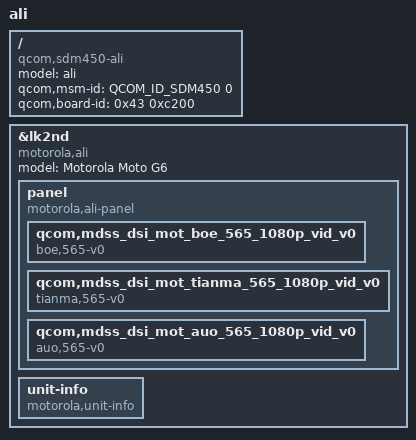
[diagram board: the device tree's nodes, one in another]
// SPDX-License-Identifier: GPL-2.0-only

#include <skeleton64.dtsi>
#include <lk2nd.dtsi>
#include <motorola-carrier-channel-ids.dtsi>

// The stock bootloader uses all these values to select the right DTB
/ {
	model = "ali";
	compatible = "qcom,sdm450-ali", "qcom,sdm450-moto", "qcom,sdm450";
	qcom,msm-id = <QCOM_ID_SDM450 0>;
  	qcom,board-id = <0x43 0xc200>;
};

&lk2nd {
	model = "Motorola Moto G6";
	compatible = "motorola,ali";
	
	panel {
		compatible = "motorola,ali-panel", "lk2nd,panel";
    
    	qcom,mdss_dsi_mot_boe_565_1080p_vid_v0 {
			compatible = "boe,565-v0";
		};
    
		qcom,mdss_dsi_mot_tianma_565_1080p_vid_v0 {
			compatible = "tianma,565-v0";
		};

		qcom,mdss_dsi_mot_auo_565_1080p_vid_v0 {
			compatible = "auo,565-v0";
		};
	};

	unit-info {
		compatible = "motorola,unit-info";
	};
};
